# ESP32-C3 register map
Vendor: ESPRESSIF SYSTEMS (SHANGHAI) CO., LTD.; Series: ESP32-C3; File version: 8
CPU: RV32IMC r0p0, little endian, no MPU, no FPU, 4 interrupt priority bits
Address unit: 32 bits
Registers are 32-bit, read-write, reset 0x0 unless marked. A register's access mark holds for its fields unless they carry their own. Offsets are from the block's base; [hi:lo] are bit positions; {n}, {i} and the like mark numbered series.

## SYSTIMER — System Timer
Base 0x60023000
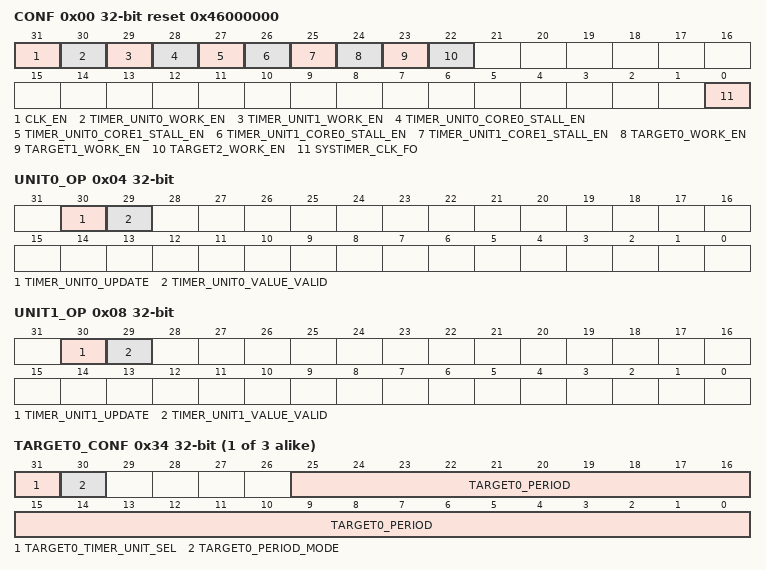
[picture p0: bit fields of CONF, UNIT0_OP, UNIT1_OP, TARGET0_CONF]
0x00 CONF reset 0x46000000 — SYSTIMER_CONF.
  [31] CLK_EN — register file clk gating
  [30] TIMER_UNIT0_WORK_EN — timer unit0 work enable
  [29] TIMER_UNIT1_WORK_EN — timer unit1 work enable
  [28] TIMER_UNIT0_CORE0_STALL_EN — If timer unit0 is stalled when core0 stalled
  [27] TIMER_UNIT0_CORE1_STALL_EN — If timer unit0 is stalled when core1 stalled
  [26] TIMER_UNIT1_CORE0_STALL_EN — If timer unit1 is stalled when core0 stalled
  [25] TIMER_UNIT1_CORE1_STALL_EN — If timer unit1 is stalled when core1 stalled
  [24] TARGET0_WORK_EN — target0 work enable
  [23] TARGET1_WORK_EN — target1 work enable
  [22] TARGET2_WORK_EN — target2 work enable
  [0] SYSTIMER_CLK_FO — systimer clock force on
0x04 UNIT0_OP access per field — SYSTIMER_UNIT0_OP.
  [30] TIMER_UNIT0_UPDATE wo — update timer_unit0
  [29] TIMER_UNIT0_VALUE_VALID ro — reg_timer_unit0_value_valid
0x08 UNIT1_OP access per field — SYSTIMER_UNIT1_OP.
  [30] TIMER_UNIT1_UPDATE wo — update timer unit1
  [29] TIMER_UNIT1_VALUE_VALID ro — timer value is sync and valid
0x0C UNIT0_LOAD_HI — SYSTIMER_UNIT0_LOAD_HI.
  [19:0] TIMER_UNIT0_LOAD_HI — timer unit0 load high 32 bit
0x10 UNIT0_LOAD_LO — SYSTIMER_UNIT0_LOAD_LO.
  [31:0] TIMER_UNIT0_LOAD_LO — timer unit0 load low 32 bit
0x14 UNIT1_LOAD_HI — SYSTIMER_UNIT1_LOAD_HI.
  [19:0] TIMER_UNIT1_LOAD_HI — timer unit1 load high 32 bit
0x18 UNIT1_LOAD_LO — SYSTIMER_UNIT1_LOAD_LO.
  [31:0] TIMER_UNIT1_LOAD_LO — timer unit1 load low 32 bit
{0x1C+8i} TARGET{i}_HI (i=0..2) — SYSTIMER_TARGET{i}_HI.
  [19:0] TIMER_TARGET{i}_HI — timer taget{i} high 32 bit
{0x20+8i} TARGET{i}_LO (i=0..2) — SYSTIMER_TARGET{i}_LO.
  [31:0] TIMER_TARGET{i}_LO — timer taget{i} low 32 bit
{0x34+4i} TARGET{i}_CONF (i=0..2) — SYSTIMER_TARGET{i}_CONF.
  [31] TARGET{i}_TIMER_UNIT_SEL — select which unit to compare
  [30] TARGET{i}_PERIOD_MODE — Set target{i} to period mode
  [25:0] TARGET{i}_PERIOD
0x40 UNIT0_VALUE_HI ro — SYSTIMER_UNIT0_VALUE_HI.
  [19:0] TIMER_UNIT0_VALUE_HI — timer read value high 32bit
0x44 UNIT0_VALUE_LO ro — SYSTIMER_UNIT0_VALUE_LO.
  [31:0] TIMER_UNIT0_VALUE_LO — timer read value low 32bit
0x48 UNIT1_VALUE_HI ro — SYSTIMER_UNIT1_VALUE_HI.
  [19:0] TIMER_UNIT1_VALUE_HI — timer read value high 32bit
0x4C UNIT1_VALUE_LO ro — SYSTIMER_UNIT1_VALUE_LO.
  [31:0] TIMER_UNIT1_VALUE_LO — timer read value low 32bit
{0x50+4i} COMP{i}_LOAD wo (i=0..2) — SYSTIMER_COMP{i}_LOAD.
  [0] TIMER_COMP{i}_LOAD — timer comp{i} load value
0x5C UNIT0_LOAD wo — SYSTIMER_UNIT0_LOAD.
  [0] TIMER_UNIT0_LOAD — timer unit0 load value
0x60 UNIT1_LOAD wo — SYSTIMER_UNIT1_LOAD.
  [0] TIMER_UNIT1_LOAD — timer unit1 load value
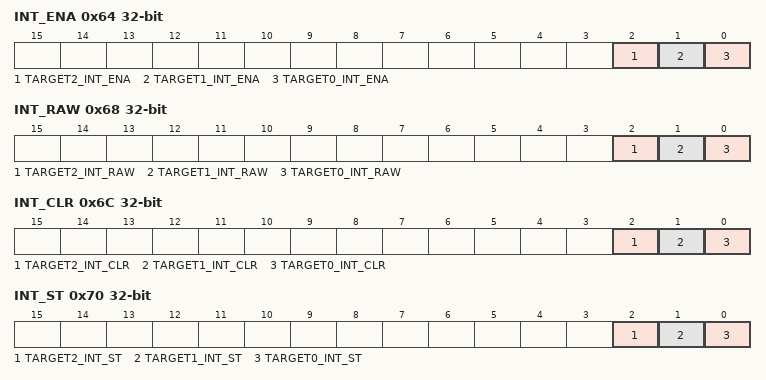
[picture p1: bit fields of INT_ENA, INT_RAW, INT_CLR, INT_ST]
0x64 INT_ENA — SYSTIMER_INT_ENA.
  [2] TARGET2_INT_ENA — interupt2 enable
  [1] TARGET1_INT_ENA — interupt1 enable
  [0] TARGET0_INT_ENA — interupt0 enable
0x68 INT_RAW ro — SYSTIMER_INT_RAW.
  [2] TARGET2_INT_RAW — interupt2 raw
  [1] TARGET1_INT_RAW — interupt1 raw
  [0] TARGET0_INT_RAW — interupt0 raw
0x6C INT_CLR wo — SYSTIMER_INT_CLR.
  [2] TARGET2_INT_CLR — interupt2 clear
  [1] TARGET1_INT_CLR — interupt1 clear
  [0] TARGET0_INT_CLR — interupt0 clear
0x70 INT_ST ro — SYSTIMER_INT_ST.
  [2] TARGET2_INT_ST — reg_target2_int_st
  [1] TARGET1_INT_ST — reg_target1_int_st
  [0] TARGET0_INT_ST — reg_target0_int_st
0xFC DATE reset 0x2006171 — SYSTIMER_DATE.
  [31:0] DATE — reg_date

## TIMG0 — Timer Group
Base 0x6001F000
Same registers: TIMG1 0x60020000
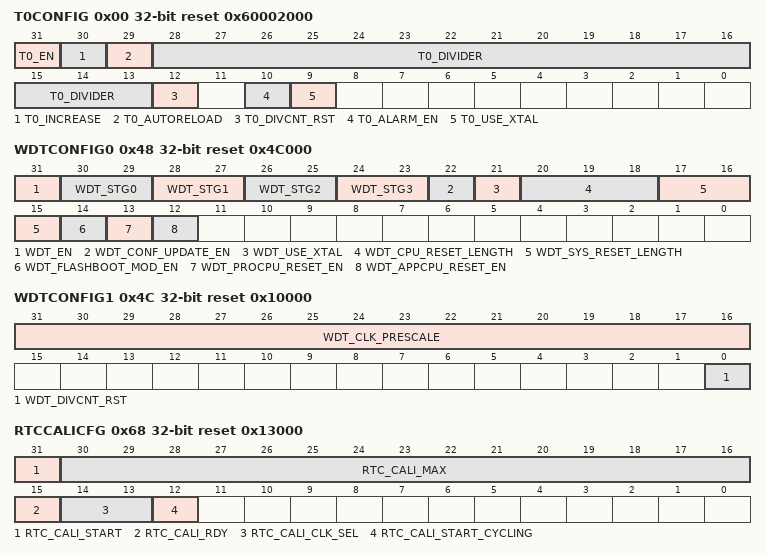
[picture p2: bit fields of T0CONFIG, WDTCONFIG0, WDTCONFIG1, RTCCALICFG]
0x00 T0CONFIG access per field reset 0x60002000 — TIMG_T0CONFIG_REG.
  [31] T0_EN rw — reg_t0_en.
  [30] T0_INCREASE rw — reg_t0_increase.
  [29] T0_AUTORELOAD rw — reg_t0_autoreload.
  [28:13] T0_DIVIDER rw — reg_t0_divider.
  [12] T0_DIVCNT_RST wo — reg_t0_divcnt_rst.
  [10] T0_ALARM_EN rw — reg_t0_alarm_en.
  [9] T0_USE_XTAL rw — reg_t0_use_xtal.
0x04 T0LO ro — TIMG_T0LO_REG.
  [31:0] T0_LO
0x08 T0HI ro — TIMG_T0HI_REG.
  [21:0] T0_HI
0x0C T0UPDATE — TIMG_T0UPDATE_REG.
  [31] T0_UPDATE
0x10 T0ALARMLO — TIMG_T0ALARMLO_REG.
  [31:0] T0_ALARM_LO — reg_t0_alarm_lo.
0x14 T0ALARMHI — TIMG_T0ALARMHI_REG.
  [21:0] T0_ALARM_HI — reg_t0_alarm_hi.
0x18 T0LOADLO — TIMG_T0LOADLO_REG.
  [31:0] T0_LOAD_LO — reg_t0_load_lo.
0x1C T0LOADHI — TIMG_T0LOADHI_REG.
  [21:0] T0_LOAD_HI — reg_t0_load_hi.
0x20 T0LOAD wo — TIMG_T0LOAD_REG.
  [31:0] T0_LOAD
0x48 WDTCONFIG0 access per field reset 0x4C000 — TIMG_WDTCONFIG0_REG.
  [31] WDT_EN rw — reg_wdt_en.
  [30-2n:29-2n] WDT_STG{n} rw (n=0..3) — reg_wdt_stg{n}.
  [22] WDT_CONF_UPDATE_EN wo — reg_wdt_conf_update_en.
  [21] WDT_USE_XTAL rw — reg_wdt_use_xtal.
  [20:18] WDT_CPU_RESET_LENGTH rw — reg_wdt_cpu_reset_length.
  [17:15] WDT_SYS_RESET_LENGTH rw — reg_wdt_sys_reset_length.
  [14] WDT_FLASHBOOT_MOD_EN rw — reg_wdt_flashboot_mod_en.
  [13] WDT_PROCPU_RESET_EN rw — reg_wdt_procpu_reset_en.
  [12] WDT_APPCPU_RESET_EN rw — reg_wdt_appcpu_reset_en.
0x4C WDTCONFIG1 access per field reset 0x10000 — TIMG_WDTCONFIG1_REG.
  [31:16] WDT_CLK_PRESCALE rw — reg_wdt_clk_prescale.
  [0] WDT_DIVCNT_RST wo — reg_wdt_divcnt_rst.
0x50 WDTCONFIG2 reset 0x18CBA80 — TIMG_WDTCONFIG2_REG.
  [31:0] WDT_STG0_HOLD — reg_wdt_stg0_hold.
0x54 WDTCONFIG3 reset 0x7FFFFFF — TIMG_WDTCONFIG3_REG.
  [31:0] WDT_STG1_HOLD — reg_wdt_stg1_hold.
0x58 WDTCONFIG4 reset 0xFFFFF — TIMG_WDTCONFIG4_REG.
  [31:0] WDT_STG2_HOLD — reg_wdt_stg2_hold.
0x5C WDTCONFIG5 reset 0xFFFFF — TIMG_WDTCONFIG5_REG.
  [31:0] WDT_STG3_HOLD — reg_wdt_stg3_hold.
0x60 WDTFEED wo — TIMG_WDTFEED_REG.
  [31:0] WDT_FEED
0x64 WDTWPROTECT reset 0x50D83AA1 — TIMG_WDTWPROTECT_REG.
  [31:0] WDT_WKEY — reg_wdt_wkey.
0x68 RTCCALICFG access per field reset 0x13000 — TIMG_RTCCALICFG_REG.
  [31] RTC_CALI_START rw — reg_rtc_cali_start.
  [30:16] RTC_CALI_MAX rw — reg_rtc_cali_max.
  [15] RTC_CALI_RDY ro
  [14:13] RTC_CALI_CLK_SEL rw — reg_rtc_cali_clk_sel.0:rtcslowclock.1:clk_80m.2:xtal_32k
  [12] RTC_CALI_START_CYCLING rw — reg_rtc_cali_start_cycling.
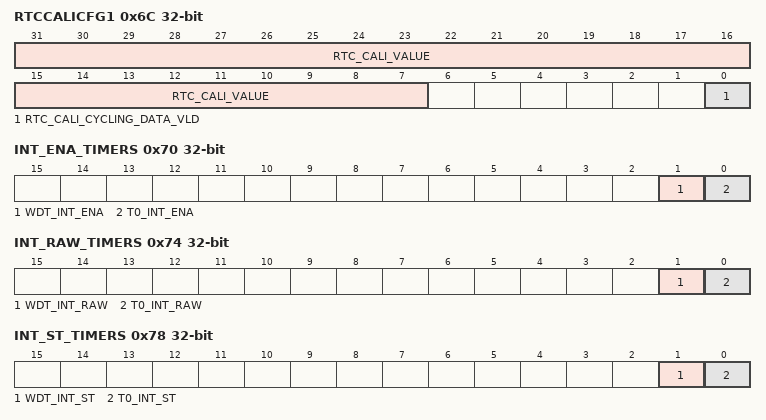
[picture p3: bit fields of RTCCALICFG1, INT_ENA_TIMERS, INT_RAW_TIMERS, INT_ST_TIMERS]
0x6C RTCCALICFG1 ro — TIMG_RTCCALICFG1_REG.
  [31:7] RTC_CALI_VALUE, [0] RTC_CALI_CYCLING_DATA_VLD
0x70 INT_ENA_TIMERS — INT_ENA_TIMG_REG
  [1] WDT_INT_ENA, [0] T0_INT_ENA
0x74 INT_RAW_TIMERS ro — INT_RAW_TIMG_REG
  [1] WDT_INT_RAW, [0] T0_INT_RAW
0x78 INT_ST_TIMERS ro — INT_ST_TIMG_REG
  [1] WDT_INT_ST, [0] T0_INT_ST
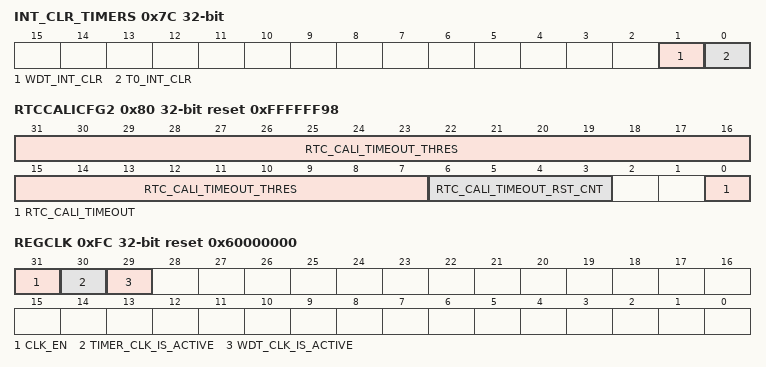
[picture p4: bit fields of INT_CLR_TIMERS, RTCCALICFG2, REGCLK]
0x7C INT_CLR_TIMERS wo — INT_CLR_TIMG_REG
  [1] WDT_INT_CLR, [0] T0_INT_CLR
0x80 RTCCALICFG2 access per field reset 0xFFFFFF98 — TIMG_RTCCALICFG2_REG.
  [31:7] RTC_CALI_TIMEOUT_THRES rw — reg_rtc_cali_timeout_thres.timeoutifcalivaluecountsoverthreshold
  [6:3] RTC_CALI_TIMEOUT_RST_CNT rw — reg_rtc_cali_timeout_rst_cnt.Cyclesthatreleasecalibrationtimeoutreset
  [0] RTC_CALI_TIMEOUT ro — timeoutindicator
0xF8 NTIMG_DATE reset 0x2006191 — TIMG_NTIMG_DATE_REG.
  [27:0] NTIMGS_DATE — reg_ntimers_date.
0xFC REGCLK reset 0x60000000 — TIMG_REGCLK_REG.
  [31] CLK_EN — reg_clk_en.
  [30] TIMER_CLK_IS_ACTIVE — reg_timer_clk_is_active.
  [29] WDT_CLK_IS_ACTIVE — reg_wdt_clk_is_active.

## XTS_AES — XTS-AES-128 Flash Encryption
Base 0x600CC000
{0x0+i} PLAIN_MEM[{i}] (i=0..15) 8-bit access not given — The memory that stores plaintext
0x40 LINESIZE — XTS-AES line-size register
  [0] LINESIZE — This bit stores the line size parameter. 0: 16Byte, 1: 32Byte.
0x44 DESTINATION — XTS-AES destination register
  [0] DESTINATION — This bit stores the destination. 0: flash(default). 1: reserved.
0x48 PHYSICAL_ADDRESS — XTS-AES physical address register
  [29:0] PHYSICAL_ADDRESS — Those bits stores the physical address. If linesize is 16-byte, the physical address should be aligned of 16 bytes. If linesize is 32-byte, the physical address should be aligned of 32 bytes.
0x4C TRIGGER wo — XTS-AES trigger register
  [0] TRIGGER — Set this bit to start manual encryption calculation
0x50 RELEASE wo — XTS-AES release register
  [0] RELEASE — Set this bit to release the manual encrypted result, after that the result will be visible to spi
0x54 DESTROY wo — XTS-AES destroy register
  [0] DESTROY — Set this bit to destroy XTS-AES result.
0x58 STATE ro — XTS-AES status register
  [1:0] STATE — Those bits shows XTS-AES status. 0=IDLE, 1=WORK, 2=RELEASE, 3=USE. IDLE means that XTS-AES is idle. WORK means that XTS-AES is busy with calculation. RELEASE means the encrypted result is generated but not visible to mspi. USE means that the encrypted result is visible to mspi.
0x5C DATE reset 0x20200623 — XTS-AES version control register
  [29:0] DATE — Those bits stores the version information of XTS-AES.
